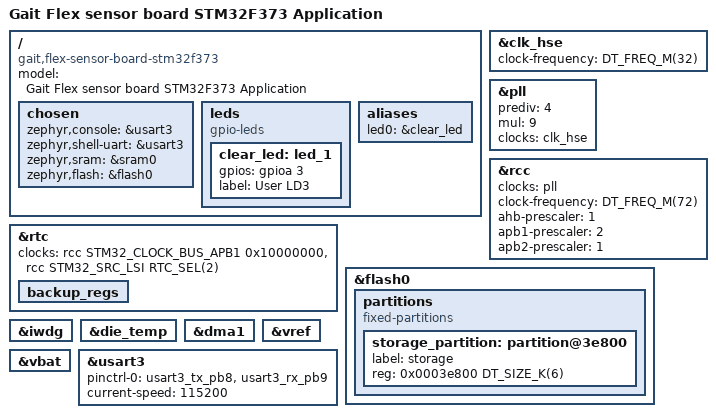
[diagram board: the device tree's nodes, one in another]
/*
 * Copyright (c) 2024 Nordic Semiconductor ASA
 *
 * SPDX-License-Identifier: Apache-2.0
 */

 /dts-v1/;
 #include <st/f3/stm32f373Xc.dtsi>
 #include <zephyr/dt-bindings/input/input-event-codes.h>
 #include <st/f3/stm32f373r(8-b-c)tx-pinctrl.dtsi>
 
 / {
     model = "Gait Flex sensor board STM32F373 Application";
     compatible = "gait,flex-sensor-board-stm32f373";
 
     chosen {
		zephyr,console = &usart3;
		zephyr,shell-uart = &usart3;
		zephyr,sram = &sram0;
		zephyr,flash = &flash0;
		
     };

	 leds {
		compatible = "gpio-leds";
		clear_led: led_1 {
			gpios = <&gpioa 3 GPIO_ACTIVE_HIGH>;
			label = "User LD3";
		};
		
	};


	aliases {
		led0 = &clear_led;
	};

 };

 &clk_hse {
	status = "okay";
	clock-frequency = <DT_FREQ_M(32)>;
};


&pll {
	prediv = <4>;
	mul = <9>;
	clocks = <&clk_hse>;
	status = "okay";
};

&rcc {
	clocks = <&pll>;
	clock-frequency = <DT_FREQ_M(72)>;
	ahb-prescaler = <1>;
	apb1-prescaler = <2>;
	apb2-prescaler = <1>;
};



&rtc {
	clocks = <&rcc STM32_CLOCK_BUS_APB1 0x10000000>,
		 <&rcc STM32_SRC_LSI RTC_SEL(2)>;
	status = "okay";

	backup_regs {
		status = "okay";
	};
};


&flash0 {
	partitions {
		compatible = "fixed-partitions";
		#address-cells = <1>;
		#size-cells = <1>;

		/* Set 6Kb of storage at the end of the 256Kb of flash */
		storage_partition: partition@3e800 {
			label = "storage";
			reg = <0x0003e800 DT_SIZE_K(6)>;
		};
	};
};

&iwdg {
	status = "okay";
};


&die_temp {
	status = "okay";
};

&dma1 {
	status = "okay";
};

&vref {
	status = "okay";
};

&vbat {
	status = "okay";
};


&usart3 {
	pinctrl-0 = <&usart3_tx_pb8 &usart3_rx_pb9>;
	pinctrl-names = "default";
	current-speed = <115200>;
	status = "okay";
};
